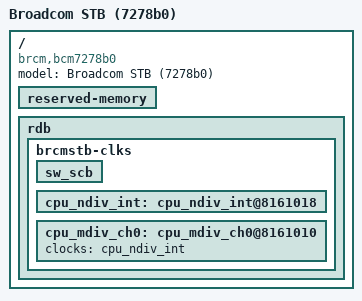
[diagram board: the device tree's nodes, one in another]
/dts-v1/;

/include/ "A53.dtsi"
/include/ "family-7278.dtsi"


/ {
	model = "Broadcom STB (7278b0)";
	compatible = "brcm,bcm7278b0", "brcm,brcmstb";

	reserved-memory {
		#address-cells = <0x2>;
		#size-cells = <0x2>;
		ranges;
	};

	rdb {
		#address-cells = <0x1>;
		#size-cells = <0x1>;

		brcmstb-clks {
			#address-cells = <0x1>;
			#size-cells = <0x1>;

			sw_scb: sw_scb {
			};

			cpu_ndiv_int: cpu_ndiv_int@8161018 {
			};

			cpu_mdiv_ch0: cpu_mdiv_ch0@8161010 {
				clocks = <&cpu_ndiv_int>;
				clock-names = "cpu_ndiv_int";
			};
		};
	};
};
